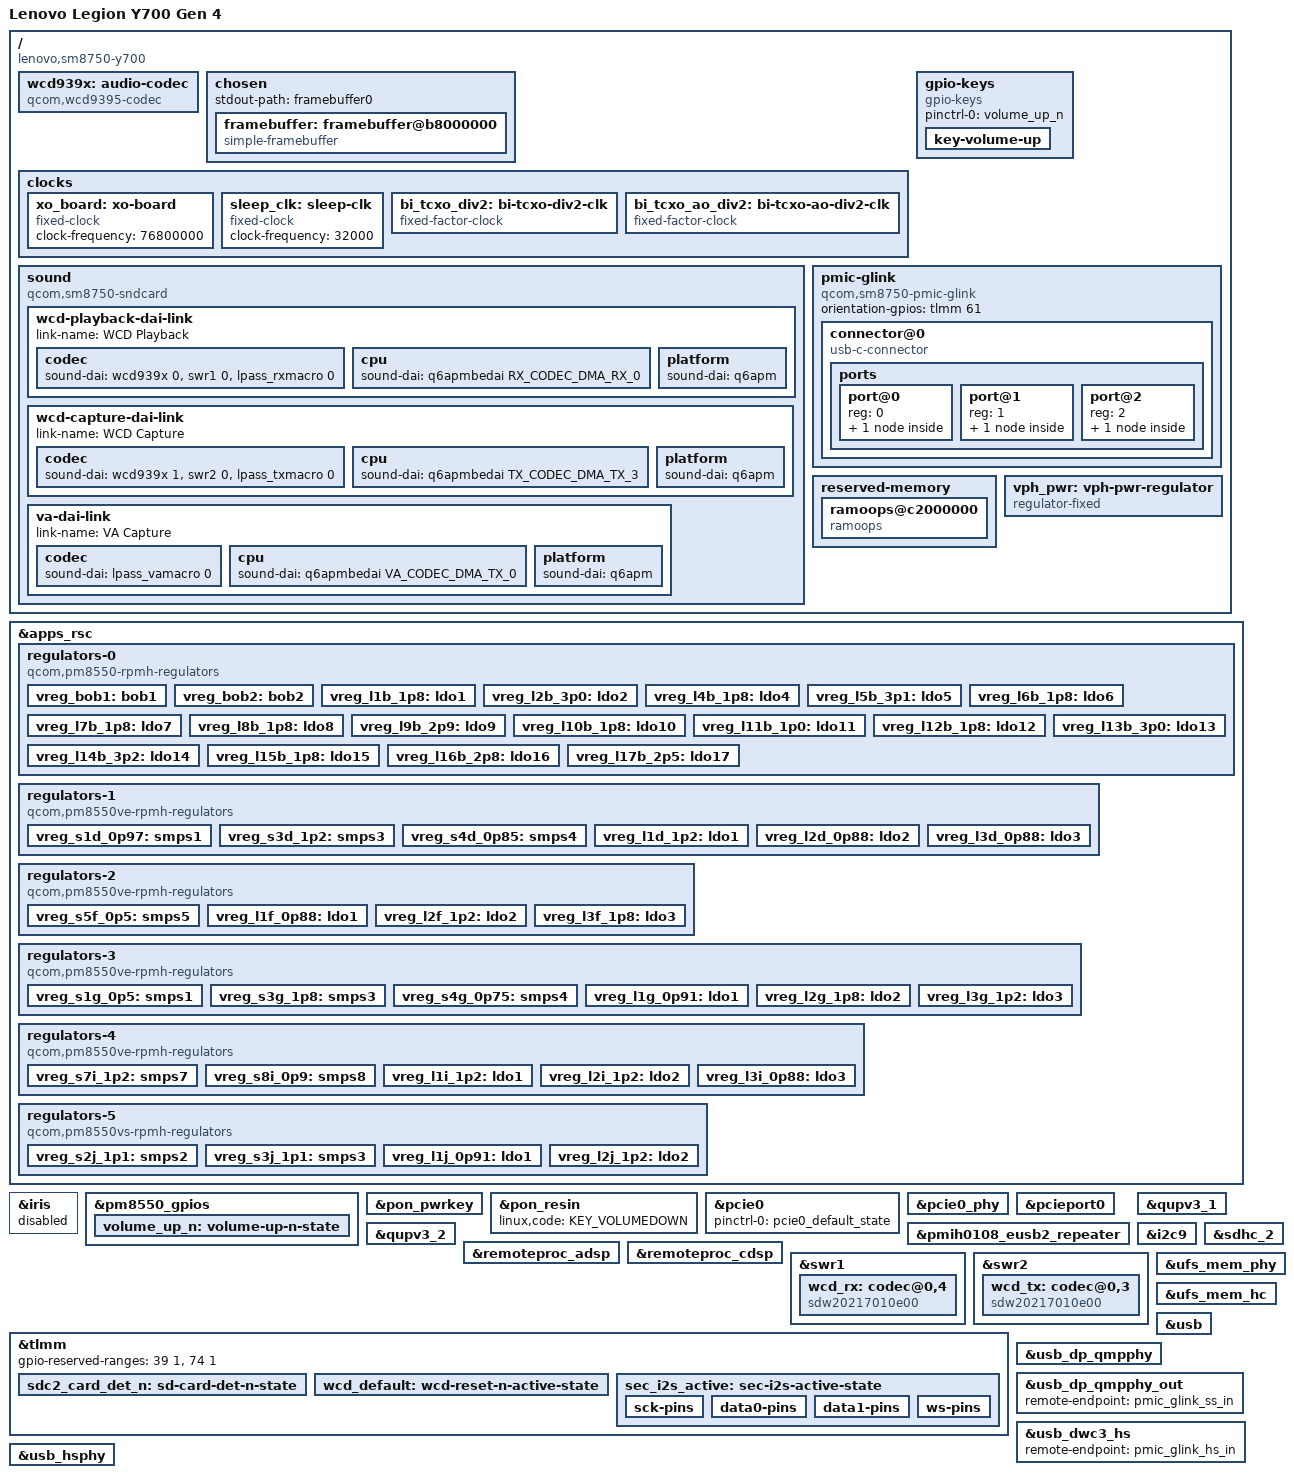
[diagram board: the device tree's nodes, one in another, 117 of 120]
// SPDX-License-Identifier: BSD-3-Clause
/*
 * Copyright (c) 2024 Qualcomm Innovation Center, Inc. All rights reserved.
 */

/dts-v1/;

#include <dt-bindings/gpio/gpio.h>
#include <dt-bindings/leds/common.h>
#include <dt-bindings/regulator/qcom,rpmh-regulator.h>
#include "sm8750.dtsi"
#include "pm8550.dtsi"
#define PMK8550VE_SID 8
#include "pm8550ve.dtsi"
#include "pmih0108.dtsi"
#include "pmk8550.dtsi"
#include "sm8750-pmics.dtsi"

/ {
	model = "Lenovo Legion Y700 Gen 4";
	compatible = "lenovo,sm8750-y700", "qcom,sm8750";
	chassis-type = "tablet";

	wcd939x: audio-codec {
		compatible = "qcom,wcd9395-codec", "qcom,wcd9390-codec";

		pinctrl-0 = <&wcd_default>;
		pinctrl-names = "default";

		qcom,micbias1-microvolt = <1800000>;
		qcom,micbias2-microvolt = <1800000>;
		qcom,micbias3-microvolt = <1800000>;
		qcom,micbias4-microvolt = <1800000>;
		qcom,mbhc-buttons-vthreshold-microvolt = <75000 150000 237000 500000 500000 500000 500000 500000>;
		qcom,mbhc-headset-vthreshold-microvolt = <1700000>;
		qcom,mbhc-headphone-vthreshold-microvolt = <50000>;
		qcom,rx-device = <&wcd_rx>;
		qcom,tx-device = <&wcd_tx>;

		reset-gpios = <&tlmm 101 GPIO_ACTIVE_LOW>;

		vdd-buck-supply = <&vreg_l15b_1p8>;
		vdd-rxtx-supply = <&vreg_l15b_1p8>;
		vdd-io-supply = <&vreg_l15b_1p8>;
		vdd-mic-bias-supply = <&vreg_bob1>;
		vdd-px-supply = <&vreg_l15b_1p8>;

		#sound-dai-cells = <1>;
	};

	chosen {
		#address-cells = <2>;
		#size-cells = <2>;
		ranges;
		stdout-path = "framebuffer0";

		framebuffer: framebuffer@b8000000 {
			compatible = "simple-framebuffer";
			reg = <0x0 0xfc800000 0x0 0x2b00000>;
			width = <1904>;
			height = <3040>;
			stride = <(1904 * 4)>;
			format = "a8r8g8b8";
		};
	};

	clocks {
		xo_board: xo-board {
			compatible = "fixed-clock";
			clock-frequency = <76800000>;
			#clock-cells = <0>;
		};

		sleep_clk: sleep-clk {
			compatible = "fixed-clock";
			clock-frequency = <32000>;
			#clock-cells = <0>;
		};

		bi_tcxo_div2: bi-tcxo-div2-clk {
			compatible = "fixed-factor-clock";
			#clock-cells = <0>;

			clocks = <&rpmhcc RPMH_CXO_CLK>;
			clock-mult = <1>;
			clock-div = <2>;
		};

		bi_tcxo_ao_div2: bi-tcxo-ao-div2-clk {
			compatible = "fixed-factor-clock";
			#clock-cells = <0>;

			clocks = <&rpmhcc RPMH_CXO_CLK_A>;
			clock-mult = <1>;
			clock-div = <2>;
		};
	};

	gpio-keys {
		compatible = "gpio-keys";

		pinctrl-0 = <&volume_up_n>;
		pinctrl-names = "default";

		key-volume-up {
			label = "Volume Up";
			linux,code = <KEY_VOLUMEUP>;
			gpios = <&pm8550_gpios 6 GPIO_ACTIVE_LOW>;
			debounce-interval = <15>;
			linux,can-disable;
			wakeup-source;
		};
	};

	sound {
		compatible = "qcom,sm8750-sndcard", "qcom,sm8450-sndcard";
		model = "LENOVO-Y700-GEN4";

		pinctrl-0 = <&sec_i2s_active>;
		pinctrl-names = "default";

		audio-routing = "SpkrLeft IN", "AmplifierL OUT",
				"SpkrRight IN", "AmplifierR OUT",
				"IN1_HPHL", "HPHL_OUT",
				"IN2_HPHR", "HPHR_OUT",
				"AMIC1", "MIC BIAS1",
				"AMIC2", "MIC BIAS2",
				"AMIC3", "MIC BIAS3",
				"AMIC4", "MIC BIAS3",
				"AMIC5", "MIC BIAS4",
				"TX SWR_INPUT0", "ADC1_OUTPUT",
				"TX SWR_INPUT1", "ADC2_OUTPUT",
				"TX SWR_INPUT2", "ADC3_OUTPUT",
				"TX SWR_INPUT3", "ADC4_OUTPUT";

		wcd-playback-dai-link {
			link-name = "WCD Playback";

			codec {
				sound-dai = <&wcd939x 0>, <&swr1 0>, <&lpass_rxmacro 0>;
			};

			cpu {
				sound-dai = <&q6apmbedai RX_CODEC_DMA_RX_0>;
			};

			platform {
				sound-dai = <&q6apm>;
			};
		};

		wcd-capture-dai-link {
			link-name = "WCD Capture";

			codec {
				sound-dai = <&wcd939x 1>, <&swr2 0>, <&lpass_txmacro 0>;
			};

			cpu {
				sound-dai = <&q6apmbedai TX_CODEC_DMA_TX_3>;
			};

			platform {
				sound-dai = <&q6apm>;
			};
		};
/*
		i2s-dai-link {
			link-name = "Speaker Playback";

			codec {
				sound-dai = <&aw88698_l 0>, <&aw88698_r 0>;
			};

			cpu {
				sound-dai = <&q6apmbedai SECONDARY_MI2S_RX>;
			};

			platform {
				sound-dai = <&q6apm>;
			};
		};
*/
		va-dai-link {
			link-name = "VA Capture";

			codec {
				sound-dai = <&lpass_vamacro 0>;
			};

			cpu {
				sound-dai = <&q6apmbedai VA_CODEC_DMA_TX_0>;
			};

			platform {
				sound-dai = <&q6apm>;
			};
		};
	};

	pmic-glink {
		compatible = "qcom,sm8750-pmic-glink",
			     "qcom,sm8550-pmic-glink",
			     "qcom,pmic-glink";
		#address-cells = <1>;
		#size-cells = <0>;
		orientation-gpios = <&tlmm 61 GPIO_ACTIVE_HIGH>;

		connector@0 {
			compatible = "usb-c-connector";
			reg = <0>;

			power-role = "dual";
			data-role = "dual";

			ports {
				#address-cells = <1>;
				#size-cells = <0>;

				port@0 {
					reg = <0>;

					pmic_glink_hs_in: endpoint {
						remote-endpoint = <&usb_dwc3_hs>;
					};
				};

				port@1 {
					reg = <1>;

					pmic_glink_ss_in: endpoint {
						remote-endpoint = <&usb_dp_qmpphy_out>;
					};
				};

				port@2 {
					reg = <2>;

					pmic_glink_sbu: endpoint {
					};
				};
			};
		};
	};

	reserved-memory {
		ramoops@c2000000 {
			compatible = "ramoops";
			reg = <0x0 0xc2000000 0x0 0x400000>;
			record-size = <0>;
			console-size = <0x200000>;
		};
	};

	vph_pwr: vph-pwr-regulator {
		compatible = "regulator-fixed";

		regulator-name = "vph_pwr";
		regulator-min-microvolt = <3700000>;
		regulator-max-microvolt = <3700000>;

		regulator-always-on;
		regulator-boot-on;
	};
};

&apps_rsc {
	regulators-0 {
		compatible = "qcom,pm8550-rpmh-regulators";

		vdd-bob1-supply = <&vph_pwr>;
		vdd-bob2-supply = <&vph_pwr>;
		vdd-l1-l4-l10-supply = <&vreg_s3g_1p8>;
		vdd-l2-l13-l14-supply = <&vreg_bob1>;
		vdd-l3-supply = <&vreg_s7i_1p2>;
		vdd-l5-l16-supply = <&vreg_bob1>;
		vdd-l6-l7-supply = <&vreg_bob1>;
		vdd-l8-l9-supply = <&vreg_bob1>;
		vdd-l11-supply = <&vreg_s7i_1p2>;
		vdd-l12-supply = <&vreg_s3g_1p8>;
		vdd-l15-supply = <&vreg_s3g_1p8>;
		vdd-l17-supply = <&vreg_bob2>;

		qcom,pmic-id = "b";

		vreg_bob1: bob1 {
			regulator-name = "vreg_bob1";
			regulator-min-microvolt = <3008000>;
			regulator-max-microvolt = <4000000>;
			regulator-initial-mode = <RPMH_REGULATOR_MODE_HPM>;
		};

		vreg_bob2: bob2 {
			regulator-name = "vreg_bob2";
			regulator-min-microvolt = <2704000>;
			regulator-max-microvolt = <3008000>;
			regulator-initial-mode = <RPMH_REGULATOR_MODE_HPM>;
		};

		vreg_l1b_1p8: ldo1 {
			regulator-name = "vreg_l1b_1p8";
			regulator-min-microvolt = <1800000>;
			regulator-max-microvolt = <1800000>;
			regulator-initial-mode = <RPMH_REGULATOR_MODE_HPM>;
			regulator-allow-set-load;
			regulator-allowed-modes = <RPMH_REGULATOR_MODE_LPM
						   RPMH_REGULATOR_MODE_HPM>;
		};

		vreg_l2b_3p0: ldo2 {
			regulator-name = "vreg_l2b_3p0";
			regulator-min-microvolt = <3008000>;
			regulator-max-microvolt = <3048000>;
			regulator-initial-mode = <RPMH_REGULATOR_MODE_HPM>;
			regulator-allow-set-load;
			regulator-allowed-modes = <RPMH_REGULATOR_MODE_LPM
						   RPMH_REGULATOR_MODE_HPM>;
		};

		vreg_l4b_1p8: ldo4 {
			regulator-name = "vreg_l4b_1p8";
			regulator-min-microvolt = <1800000>;
			regulator-max-microvolt = <1800000>;
			regulator-initial-mode = <RPMH_REGULATOR_MODE_HPM>;
			regulator-allow-set-load;
			regulator-allowed-modes = <RPMH_REGULATOR_MODE_LPM
						   RPMH_REGULATOR_MODE_HPM>;
		};

		vreg_l5b_3p1: ldo5 {
			regulator-name = "vreg_l5b_3p1";
			regulator-min-microvolt = <3100000>;
			regulator-max-microvolt = <3148000>;
			regulator-initial-mode = <RPMH_REGULATOR_MODE_HPM>;
			regulator-allow-set-load;
			regulator-allowed-modes = <RPMH_REGULATOR_MODE_LPM
						   RPMH_REGULATOR_MODE_HPM>;
		};

		vreg_l6b_1p8: ldo6 {
			regulator-name = "vreg_l6b_1p8";
			regulator-min-microvolt = <1800000>;
			regulator-max-microvolt = <3008000>;
			regulator-initial-mode = <RPMH_REGULATOR_MODE_HPM>;
			regulator-allow-set-load;
			regulator-allowed-modes = <RPMH_REGULATOR_MODE_LPM
						   RPMH_REGULATOR_MODE_HPM>;
		};

		vreg_l7b_1p8: ldo7 {
			regulator-name = "vreg_l7b_1p8";
			regulator-min-microvolt = <1800000>;
			regulator-max-microvolt = <3008000>;
			regulator-initial-mode = <RPMH_REGULATOR_MODE_HPM>;
			regulator-allow-set-load;
			regulator-allowed-modes = <RPMH_REGULATOR_MODE_LPM
						   RPMH_REGULATOR_MODE_HPM>;
		};

		vreg_l8b_1p8: ldo8 {
			regulator-name = "vreg_l8b_1p8";
			regulator-min-microvolt = <1800000>;
			regulator-max-microvolt = <3008000>;
			regulator-initial-mode = <RPMH_REGULATOR_MODE_HPM>;
			regulator-allow-set-load;
			regulator-allowed-modes = <RPMH_REGULATOR_MODE_LPM
						   RPMH_REGULATOR_MODE_HPM>;
		};

		vreg_l9b_2p9: ldo9 {
			regulator-name = "vreg_l9b_2p9";
			regulator-min-microvolt = <2960000>;
			regulator-max-microvolt = <3008000>;
			regulator-initial-mode = <RPMH_REGULATOR_MODE_HPM>;
			regulator-allow-set-load;
			regulator-allowed-modes = <RPMH_REGULATOR_MODE_LPM
						   RPMH_REGULATOR_MODE_HPM>;
		};

		vreg_l10b_1p8: ldo10 {
			regulator-name = "vreg_l10b_1p8";
			regulator-min-microvolt = <1800000>;
			regulator-max-microvolt = <1800000>;
			regulator-initial-mode = <RPMH_REGULATOR_MODE_HPM>;
			regulator-allow-set-load;
			regulator-allowed-modes = <RPMH_REGULATOR_MODE_LPM
						   RPMH_REGULATOR_MODE_HPM>;
		};

		vreg_l11b_1p0: ldo11 {
			regulator-name = "vreg_l11b_1p0";
			regulator-min-microvolt = <1064000>;
			regulator-max-microvolt = <1292000>;
			regulator-initial-mode = <RPMH_REGULATOR_MODE_HPM>;
			regulator-allow-set-load;
			regulator-allowed-modes = <RPMH_REGULATOR_MODE_LPM
						   RPMH_REGULATOR_MODE_HPM>;
		};

		vreg_l12b_1p8: ldo12 {
			regulator-name = "vreg_l12b_1p8";
			regulator-min-microvolt = <1200000>;
			regulator-max-microvolt = <1800000>;
			regulator-initial-mode = <RPMH_REGULATOR_MODE_HPM>;
			regulator-allow-set-load;
			regulator-allowed-modes = <RPMH_REGULATOR_MODE_LPM
						   RPMH_REGULATOR_MODE_HPM>;
		};

		vreg_l13b_3p0: ldo13 {
			regulator-name = "vreg_l13b_3p0";
			regulator-min-microvolt = <3000000>;
			regulator-max-microvolt = <3000000>;
			regulator-initial-mode = <RPMH_REGULATOR_MODE_HPM>;
			regulator-allow-set-load;
			regulator-allowed-modes = <RPMH_REGULATOR_MODE_LPM
						   RPMH_REGULATOR_MODE_HPM>;
		};

		vreg_l14b_3p2: ldo14 {
			regulator-name = "vreg_l14b_3p2";
			regulator-min-microvolt = <3200000>;
			regulator-max-microvolt = <3200000>;
			regulator-initial-mode = <RPMH_REGULATOR_MODE_HPM>;
			regulator-allow-set-load;
			regulator-allowed-modes = <RPMH_REGULATOR_MODE_LPM
						   RPMH_REGULATOR_MODE_HPM>;
		};

		vreg_l15b_1p8: ldo15 {
			regulator-name = "vreg_l15b_1p8";
			regulator-min-microvolt = <1800000>;
			regulator-max-microvolt = <1800000>;
			regulator-initial-mode = <RPMH_REGULATOR_MODE_HPM>;
			regulator-allow-set-load;
			regulator-allowed-modes = <RPMH_REGULATOR_MODE_LPM
						   RPMH_REGULATOR_MODE_HPM>;
		};

		vreg_l16b_2p8: ldo16 {
			regulator-name = "vreg_l16b_2p8";
			regulator-min-microvolt = <2800000>;
			regulator-max-microvolt = <2800000>;
			regulator-initial-mode = <RPMH_REGULATOR_MODE_HPM>;
			regulator-allow-set-load;
			regulator-allowed-modes = <RPMH_REGULATOR_MODE_LPM
						   RPMH_REGULATOR_MODE_HPM>;
		};

		vreg_l17b_2p5: ldo17 {
			regulator-name = "vreg_l17b_2p5";
			regulator-min-microvolt = <2504000>;
			regulator-max-microvolt = <2504000>;
			regulator-initial-mode = <RPMH_REGULATOR_MODE_HPM>;
			regulator-allow-set-load;
			regulator-allowed-modes = <RPMH_REGULATOR_MODE_LPM
						   RPMH_REGULATOR_MODE_HPM>;
		};
	};

	regulators-1 {
		compatible = "qcom,pm8550ve-rpmh-regulators";

		vdd-l1-supply = <&vreg_s7i_1p2>;
		vdd-l2-supply = <&vreg_s1d_0p97>;
		vdd-l3-supply = <&vreg_s1d_0p97>;
		vdd-s1-supply = <&vph_pwr>;
		vdd-s3-supply = <&vph_pwr>;
		vdd-s4-supply = <&vph_pwr>;

		qcom,pmic-id = "d";

		vreg_s1d_0p97: smps1 {
			regulator-name = "vreg_s1d_0p97";
			regulator-min-microvolt = <880000>;
			regulator-max-microvolt = <1100000>;
			regulator-initial-mode = <RPMH_REGULATOR_MODE_HPM>;
		};

		vreg_s3d_1p2: smps3 {
			regulator-name = "vreg_s3d_1p2";
			regulator-min-microvolt = <1200000>;
			regulator-max-microvolt = <1300000>;
			regulator-initial-mode = <RPMH_REGULATOR_MODE_HPM>;
		};

		vreg_s4d_0p85: smps4 {
			regulator-name = "vreg_s4d_0p85";
			regulator-min-microvolt = <500000>;
			regulator-max-microvolt = <1036000>;
			regulator-initial-mode = <RPMH_REGULATOR_MODE_HPM>;
		};

		vreg_l1d_1p2: ldo1 {
			regulator-name = "vreg_l1d_1p2";
			regulator-min-microvolt = <1200000>;
			regulator-max-microvolt = <1200000>;
			regulator-initial-mode = <RPMH_REGULATOR_MODE_HPM>;
			regulator-allow-set-load;
			regulator-allowed-modes = <RPMH_REGULATOR_MODE_LPM
						   RPMH_REGULATOR_MODE_HPM>;
		};

		vreg_l2d_0p88: ldo2 {
			regulator-name = "vreg_l2d_0p88";
			regulator-min-microvolt = <880000>;
			regulator-max-microvolt = <912000>;
			regulator-initial-mode = <RPMH_REGULATOR_MODE_HPM>;
			regulator-allow-set-load;
			regulator-allowed-modes = <RPMH_REGULATOR_MODE_LPM
						   RPMH_REGULATOR_MODE_HPM>;
		};

		vreg_l3d_0p88: ldo3 {
			regulator-name = "vreg_l3d_0p88";
			regulator-min-microvolt = <880000>;
			regulator-max-microvolt = <920000>;
			regulator-initial-mode = <RPMH_REGULATOR_MODE_HPM>;
			regulator-allow-set-load;
			regulator-allowed-modes = <RPMH_REGULATOR_MODE_LPM
						   RPMH_REGULATOR_MODE_HPM>;
		};
	};

	regulators-2 {
		compatible = "qcom,pm8550ve-rpmh-regulators";

		vdd-l1-supply = <&vreg_s1d_0p97>;
		vdd-l2-supply = <&vreg_s7i_1p2>;
		vdd-l3-supply = <&vreg_s3g_1p8>;
		vdd-s5-supply = <&vph_pwr>;

		qcom,pmic-id = "f";

		vreg_s5f_0p5: smps5 {
			regulator-name = "vreg_s5f_0p5";
			regulator-min-microvolt = <500000>;
			regulator-max-microvolt = <1000000>;
			regulator-initial-mode = <RPMH_REGULATOR_MODE_HPM>;
		};

		vreg_l1f_0p88: ldo1 {
			regulator-name = "vreg_l1f_0p88";
			regulator-min-microvolt = <880000>;
			regulator-max-microvolt = <920000>;
			regulator-initial-mode = <RPMH_REGULATOR_MODE_HPM>;
			regulator-allow-set-load;
			regulator-allowed-modes = <RPMH_REGULATOR_MODE_LPM
						   RPMH_REGULATOR_MODE_HPM>;
		};

		vreg_l2f_1p2: ldo2 {
			regulator-name = "vreg_l2f_1p2";
			regulator-min-microvolt = <1200000>;
			regulator-max-microvolt = <1200000>;
			regulator-initial-mode = <RPMH_REGULATOR_MODE_HPM>;
			regulator-allow-set-load;
			regulator-allowed-modes = <RPMH_REGULATOR_MODE_LPM
						   RPMH_REGULATOR_MODE_HPM>;
		};

		vreg_l3f_1p8: ldo3 {
			regulator-name = "vreg_l3f_1p8";
			regulator-min-microvolt = <1800000>;
			regulator-max-microvolt = <1800000>;
			regulator-initial-mode = <RPMH_REGULATOR_MODE_HPM>;
			regulator-allow-set-load;
			regulator-allowed-modes = <RPMH_REGULATOR_MODE_LPM
						   RPMH_REGULATOR_MODE_HPM>;
		};

	};

	regulators-3 {
		compatible = "qcom,pm8550ve-rpmh-regulators";

		vdd-l1-supply = <&vreg_s1d_0p97>;
		vdd-l2-supply = <&vreg_s3g_1p8>;
		vdd-l3-supply = <&vreg_s7i_1p2>;
		vdd-s1-supply = <&vph_pwr>;
		vdd-s3-supply = <&vph_pwr>;

		qcom,pmic-id = "g";

		vreg_s1g_0p5: smps1 {
			regulator-name = "vreg_s1g_0p5";
			regulator-min-microvolt = <300000>;
			regulator-max-microvolt = <700000>;
			regulator-initial-mode = <RPMH_REGULATOR_MODE_HPM>;
		};

		vreg_s3g_1p8: smps3 {
			regulator-name = "vreg_s3g_1p8";
			regulator-min-microvolt = <1856000>;
			regulator-max-microvolt = <2000000>;
			regulator-initial-mode = <RPMH_REGULATOR_MODE_LPM>;
			regulator-allow-set-load;
			regulator-allowed-modes = <RPMH_REGULATOR_MODE_LPM
						   RPMH_REGULATOR_MODE_HPM>;
		};

		vreg_s4g_0p75: smps4 {
			regulator-name = "vreg_s4g_0p75";
			regulator-min-microvolt = <300000>;
			regulator-max-microvolt = <900000>;
			regulator-initial-mode = <RPMH_REGULATOR_MODE_HPM>;
		};

		vreg_l1g_0p91: ldo1 {
			regulator-name = "vreg_l1g_0p91";
			regulator-min-microvolt = <912000>;
			regulator-max-microvolt = <936000>;
			regulator-initial-mode = <RPMH_REGULATOR_MODE_HPM>;
			regulator-allow-set-load;
			regulator-allowed-modes = <RPMH_REGULATOR_MODE_LPM
						   RPMH_REGULATOR_MODE_HPM>;
		};

		vreg_l2g_1p8: ldo2 {
			regulator-name = "vreg_l2g_1p8";
			regulator-min-microvolt = <1200000>;
			regulator-max-microvolt = <1860000>;
			regulator-initial-mode = <RPMH_REGULATOR_MODE_HPM>;
			regulator-allow-set-load;
			regulator-allowed-modes = <RPMH_REGULATOR_MODE_LPM
						   RPMH_REGULATOR_MODE_HPM>;
		};

		vreg_l3g_1p2: ldo3 {
			regulator-name = "vreg_l3g_1p2";
			regulator-min-microvolt = <1200000>;
			regulator-max-microvolt = <1256000>;
			regulator-initial-mode = <RPMH_REGULATOR_MODE_HPM>;
			regulator-allow-set-load;
			regulator-allowed-modes = <RPMH_REGULATOR_MODE_LPM
						   RPMH_REGULATOR_MODE_HPM>;
		};
	};

	regulators-4 {
		compatible = "qcom,pm8550ve-rpmh-regulators";

		vdd-l1-supply = <&vreg_s7i_1p2>;
		vdd-l2-supply = <&vreg_s7i_1p2>;
		vdd-l3-supply = <&vreg_s1d_0p97>;
		vdd-s7-supply = <&vph_pwr>;
		vdd-s8-supply = <&vph_pwr>;

		qcom,pmic-id = "i";

		vreg_s7i_1p2: smps7 {
			regulator-name = "vreg_s7i_1p2";
			regulator-min-microvolt = <1224000>;
			regulator-max-microvolt = <1340000>;
			regulator-initial-mode = <RPMH_REGULATOR_MODE_HPM>;
		};

		vreg_s8i_0p9: smps8 {
			regulator-name = "vreg_s8i_0p9";
			regulator-min-microvolt = <900000>;
			regulator-max-microvolt = <972000>;
			regulator-initial-mode = <RPMH_REGULATOR_MODE_HPM>;
		};

		vreg_l1i_1p2: ldo1 {
			regulator-name = "vreg_l1i_1p2";
			regulator-min-microvolt = <1200000>;
			regulator-max-microvolt = <1200000>;
			regulator-initial-mode = <RPMH_REGULATOR_MODE_HPM>;
			regulator-allow-set-load;
			regulator-allowed-modes = <RPMH_REGULATOR_MODE_LPM
						   RPMH_REGULATOR_MODE_HPM>;
		};

		vreg_l2i_1p2: ldo2 {
			regulator-name = "vreg_l2i_1p2";
			regulator-min-microvolt = <1200000>;
			regulator-max-microvolt = <1200000>;
			regulator-initial-mode = <RPMH_REGULATOR_MODE_HPM>;
			regulator-allow-set-load;
			regulator-allowed-modes = <RPMH_REGULATOR_MODE_LPM
						   RPMH_REGULATOR_MODE_HPM>;
		};

		vreg_l3i_0p88: ldo3 {
			regulator-name = "vreg_l3i_0p88";
			regulator-min-microvolt = <880000>;
			regulator-max-microvolt = <912000>;
			regulator-initial-mode = <RPMH_REGULATOR_MODE_HPM>;
			regulator-allow-set-load;
			regulator-allowed-modes = <RPMH_REGULATOR_MODE_LPM
						   RPMH_REGULATOR_MODE_HPM>;
		};
	};

	regulators-5 {
		compatible = "qcom,pm8550vs-rpmh-regulators";

		vdd-l1-supply = <&vreg_s1d_0p97>;
		vdd-l2-supply = <&vreg_s7i_1p2>;
		vdd-s2-supply = <&vph_pwr>;
		vdd-s3-supply = <&vph_pwr>;

		qcom,pmic-id = "j";

		vreg_s2j_1p1: smps2 {
			regulator-name = "vreg_s2j_1p1";
			regulator-min-microvolt = <1000000>;
			regulator-max-microvolt = <1100000>;
			regulator-initial-mode = <RPMH_REGULATOR_MODE_HPM>;
		};

		vreg_s3j_1p1: smps3 {
			regulator-name = "vreg_s3j_1p1";
			regulator-min-microvolt = <1000000>;
			regulator-max-microvolt = <1100000>;
			regulator-initial-mode = <RPMH_REGULATOR_MODE_HPM>;
		};


		vreg_l1j_0p91: ldo1 {
			regulator-name = "vreg_l1j_0p91";
			regulator-min-microvolt = <880000>;
			regulator-max-microvolt = <920000>;
			regulator-initial-mode = <RPMH_REGULATOR_MODE_HPM>;
			regulator-allow-set-load;
			regulator-allowed-modes = <RPMH_REGULATOR_MODE_LPM
						   RPMH_REGULATOR_MODE_HPM>;
		};

		vreg_l2j_1p2: ldo2 {
			regulator-name = "vreg_l2j_1p2";
			regulator-min-microvolt = <1200000>;
			regulator-max-microvolt = <1200000>;
			regulator-initial-mode = <RPMH_REGULATOR_MODE_HPM>;
			regulator-allow-set-load;
			regulator-allowed-modes = <RPMH_REGULATOR_MODE_LPM
						   RPMH_REGULATOR_MODE_HPM>;
		};
	};
};

&iris {
	firmware-name = "qcom/sm8750/lenovo/y700/vpu35_p4.mbn";
	status = "disabled";
};

&pm8550_gpios {
	volume_up_n: volume-up-n-state {
		pins = "gpio6";
		function = "normal";
		bias-pull-up;
		input-enable;
		power-source = <1>;
	};
};

&pon_pwrkey {
	status = "okay";
};

&pon_resin {
	linux,code = <KEY_VOLUMEDOWN>;

	status = "okay";
};

&pcie0 {
	pinctrl-0 = <&pcie0_default_state>;
	pinctrl-names = "default";

	status = "okay";
};

&pcie0_phy {
	vdda-phy-supply = <&vreg_l1f_0p88>;
	vdda-pll-supply = <&vreg_l3g_1p2>;

	status = "okay";
};

&pcieport0 {
	wake-gpios = <&tlmm 104 GPIO_ACTIVE_HIGH>;
	reset-gpios = <&tlmm 102 GPIO_ACTIVE_LOW>;
/*
	wifi@0 {
		compatible = "pci17cb,1107";
	};
*/
};

&pmih0108_eusb2_repeater {
	status = "okay";

	vdd18-supply = <&vreg_l15b_1p8>;
	vdd3-supply = <&vreg_l5b_3p1>;
};

&qupv3_1 {
	status = "okay";
};

&qupv3_2 {
	status = "okay";
};

&i2c9 {
	status = "okay";
	/* Two aw88698QNR Smart PA*/
/*
	aw88698_l: aw88698-left@34 {
		compatible = "awinic,aw88698";
		reg = <0x34>;

		awinic,audio-channel = <1>;
		awinic,sync-flag;
		firmware-name = "qcom/sm8750/lenovo/y700/aw88698_acf.bin";
		pinctrl-names = "default"; 
		pinctrl-0 = <&aw88698_left_active>;

		sound-name-prefix = "AmplifierL";
		#sound-dai-cells = <0>;
	};

	aw88698_r: aw88698-right@37 {
		compatible = "awinic,aw88698";
		reg = <0x37>;

		awinic,audio-channel = <2>;
		awinic,sync-flag;
		firmware-name = "qcom/sm8750/lenovo/y700/aw88698_acf.bin";
		pinctrl-names = "default";
		pinctrl-0 = <&aw88698_right_active>;

		sound-name-prefix = "AmplifierR";
		#sound-dai-cells = <0>;
	};
*/

};

&remoteproc_adsp {
	firmware-name = "qcom/sm8750/lenovo/y700/adsp.mbn",
			"qcom/sm8750/lenovo/y700/adsp_dtb.mbn";

	status = "okay";
};

&remoteproc_cdsp {
	firmware-name = "qcom/sm8750/lenovo/y700/cdsp.mbn",
			"qcom/sm8750/lenovo/y700/cdsp_dtb.mbn";

	status = "okay";
};

&sdhc_2 {
	cd-gpios = <&tlmm 55 GPIO_ACTIVE_LOW>;

	vmmc-supply = <&vreg_l9b_2p9>;
	vqmmc-supply = <&vreg_l8b_1p8>;

	no-sdio;
	no-mmc;

	pinctrl-0 = <&sdc2_default &sdc2_card_det_n>;
	pinctrl-1 = <&sdc2_sleep &sdc2_card_det_n>;
	pinctrl-names = "default", "sleep";

	status = "okay";
};

&swr1 {
	status = "okay";

	/* WCD9395 RX */
	wcd_rx: codec@0,4 {
		compatible = "sdw20217010e00";
		reg = <0 4>;

		/*
		 * WCD9395 RX Port 1 (HPH_L/R)      <=> SWR1 Port 1 (HPH_L/R)
		 * WCD9395 RX Port 2 (CLSH)         <=> SWR1 Port 2 (CLSH)
		 * WCD9395 RX Port 3 (COMP_L/R)     <=> SWR1 Port 3 (COMP_L/R)
		 * WCD9395 RX Port 4 (LO)           <=> SWR1 Port 4 (LO)
		 * WCD9395 RX Port 5 (DSD_L/R)      <=> SWR1 Port 5 (DSD_L/R)
		 * WCD9395 RX Port 6 (HIFI_PCM_L/R) <=> SWR1 Port 9 (HIFI_PCM_L/R)
		 */
		qcom,rx-port-mapping = <1 2 3 4 5 9>;
	};
};

&swr2 {
	status = "okay";

	/* WCD9395 TX */
	wcd_tx: codec@0,3 {
		compatible = "sdw20217010e00";
		reg = <0 3>;

		/*
		 * WCD9395 TX Port 1 (ADC1,2,3,4)         <=> SWR2 Port 2 (TX SWR_INPUT 0,1,2,3)
		 * WCD9395 TX Port 2 (ADC3,4 & DMIC0,1)   <=> SWR2 Port 2 (TX SWR_INPUT 0,1,2,3)
		 * WCD9395 TX Port 3 (DMIC0,1,2,3 & MBHC) <=> SWR2 Port 3 (TX SWR_INPUT 4,5,6,7)
		 * WCD9395 TX Port 4 (DMIC4,5,6,7)        <=> SWR2 Port 4 (TX SWR_INPUT 8,9,10,11)
		 */
		qcom,tx-port-mapping = <2 2 3 4>;
	};
};

&tlmm {
	/* reserved for secure world */
	gpio-reserved-ranges = <39 1>, <74 1>;
/*
	aw88698_left_active: aw88698-left-active-state {
		pins = "gpio120";
		function = "gpio";
		drive-strength = <2>;
		output-high;
	};

	aw88698_right_active: aw88698-right-active-state {
		pins = "gpio128";
		function = "gpio";
		drive-strength = <2>;
		output-high;
	};
*/
	sdc2_card_det_n: sd-card-det-n-state {
		pins = "gpio55";
		function = "gpio";
		drive-strength = <2>;
		bias-pull-up;
	};

	wcd_default: wcd-reset-n-active-state {
		pins = "gpio101";
		function = "gpio";
		drive-strength = <16>;
		bias-disable;
		output-low;
	};

	sec_i2s_active: sec-i2s-active-state {
		sck-pins {
			pins = "gpio121";
			function = "i2s1_sck";
			drive-strength = <8>;
			bias-disable;
		};

		data0-pins {
			pins = "gpio122";
			function = "i2s1_data0";
			drive-strength = <8>;
			bias-disable;
		};
		
		data1-pins {
			pins = "gpio124";
			function = "i2s1_data1";
			drive-strength = <8>;
			bias-disable;
		};

		ws-pins {
			pins = "gpio123";
			function = "i2s1_ws";
			drive-strength = <8>;
			output-high;
		};
	};
};

&ufs_mem_phy {
	vdda-phy-supply = <&vreg_l1j_0p91>;
	vdda-pll-supply = <&vreg_l3g_1p2>;

	status = "okay";
};

&ufs_mem_hc {
	reset-gpios = <&tlmm 215 GPIO_ACTIVE_LOW>;

	vcc-supply = <&vreg_l17b_2p5>;
	vcc-max-microamp = <1300000>;
	vccq-supply = <&vreg_l1d_1p2>;
	vccq-max-microamp = <1200000>;

	status = "okay";
};

&usb {
	status = "okay";
};

&usb_dp_qmpphy {
	vdda-phy-supply = <&vreg_l3g_1p2>;
	vdda-pll-supply = <&vreg_l2d_0p88>;

	status = "okay";
};

&usb_dp_qmpphy_out {
	remote-endpoint = <&pmic_glink_ss_in>;
};

&usb_dwc3_hs {
	remote-endpoint = <&pmic_glink_hs_in>;
};

&usb_hsphy {
	vdd-supply = <&vreg_l2d_0p88>;
	vdda12-supply = <&vreg_l3g_1p2>;

	phys = <&pmih0108_eusb2_repeater>;

	status = "okay";
};
